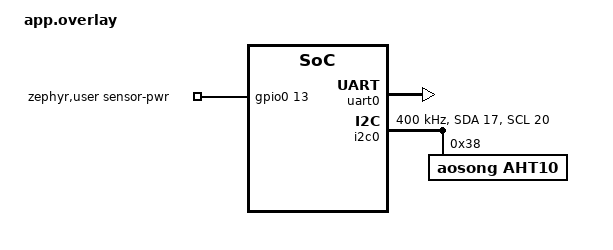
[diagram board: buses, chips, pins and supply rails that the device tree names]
#include <dt-bindings/gpio/gpio.h>

&uart0 {
    status = "okay";
    /delete-property/ hw-flow-control;
};

&i2c0 {
    status = "okay";
    clock-frequency = <400000>;

    sda-pin = <17>;
    scl-pin = <20>;

    aht10: aht10@38 {
        compatible = "aosong,aht10";
        reg = <0x38>;
    };
};

/ {
    zephyr,user {
        sensor-pwr-gpios = <&gpio0 13 GPIO_ACTIVE_HIGH>;
        /* Room id broadcast by this sensor. Values match sensor_location_t
         * in weather_proto.h:
         *   0=UNKNOWN, 1=OUTDOOR_1, 2=OUTDOOR_2, 3=OUTDOOR_3,
         *   4=LIVING_ROOM, 5=BEDROOM, 6=KITCHEN, 7=TOILET
         */
        sensor-location = <1>;
    };
};
